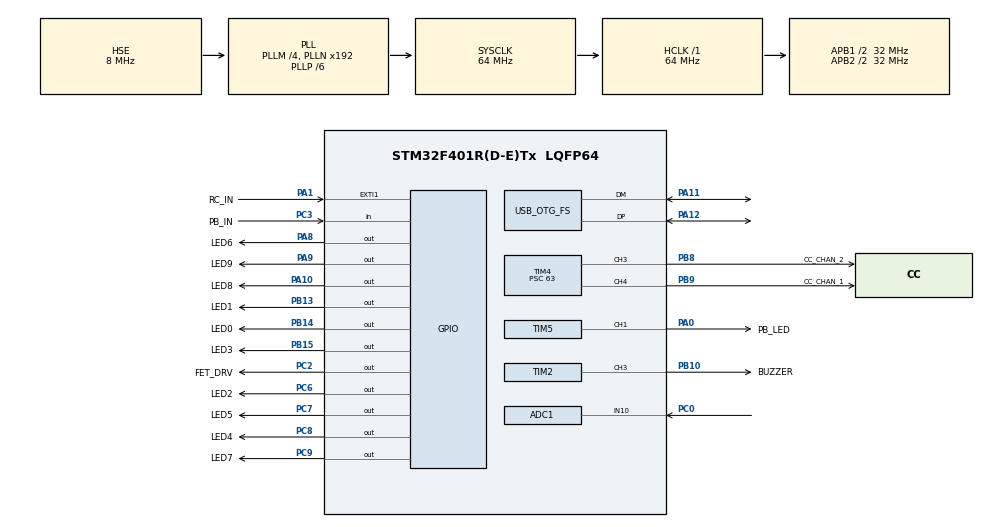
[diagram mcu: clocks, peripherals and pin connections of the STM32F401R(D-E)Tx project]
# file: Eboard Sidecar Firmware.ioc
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ADC1.Channel-4\#ChannelRegularConversion=ADC_CHANNEL_10
ADC1.ContinuousConvMode=ENABLE
ADC1.NbrOfConversionFlag=1
ADC1.Rank-4\#ChannelRegularConversion=1
ADC1.SamplingTime-4\#ChannelRegularConversion=ADC_SAMPLETIME_3CYCLES
ADC1.master=1
Dma.ADC1.0.Direction=DMA_PERIPH_TO_MEMORY
Dma.ADC1.0.FIFOMode=DMA_FIFOMODE_DISABLE
Dma.ADC1.0.Instance=DMA2_Stream0
Dma.ADC1.0.MemDataAlignment=DMA_MDATAALIGN_HALFWORD
Dma.ADC1.0.MemInc=DMA_MINC_ENABLE
Dma.ADC1.0.Mode=DMA_NORMAL
Dma.ADC1.0.PeriphDataAlignment=DMA_PDATAALIGN_HALFWORD
Dma.ADC1.0.PeriphInc=DMA_PINC_DISABLE
Dma.ADC1.0.Priority=DMA_PRIORITY_HIGH
Dma.Request0=ADC1
FREERTOS.INCLUDE_xEventGroupSetBitFromISR=1
FREERTOS.Tasks01=state_machine,8,512,doStateMachine,Default,NULL,Dynamic,NULL,NULL
FREERTOS.configCHECK_FOR_STACK_OVERFLOW=2
FREERTOS.configMAX_TASK_NAME_LEN=32
FREERTOS.configRECORD_STACK_HIGH_ADDRESS=1
FREERTOS.configTIMER_TASK_PRIORITY=48
FREERTOS.configTOTAL_HEAP_SIZE=32768
Mcu.Family=STM32F4
Mcu.Name=STM32F401R(D-E)Tx
Mcu.Package=LQFP64
NVIC.DMA2_Stream0_IRQn=true\:9\:0\:true\:false\:true\:true\:false\:true
NVIC.EXTI1_IRQn=true\:7\:0\:true\:false\:true\:false\:true\:true
NVIC.OTG_FS_IRQn=true\:6\:0\:true\:false\:true\:true\:false\:true
NVIC.PriorityGroup=NVIC_PRIORITYGROUP_4
NVIC.TIM1_TRG_COM_TIM11_IRQn=true\:0\:0\:false\:false\:true\:false\:false\:true
NVIC.TIM3_IRQn=true\:8\:0\:true\:false\:true\:true\:true\:true
NVIC.TimeBase=TIM1_TRG_COM_TIM11_IRQn
NVIC.TimeBaseIP=TIM11
PA0-WKUP.GPIO_Label=PB_LED
PA0-WKUP.Signal=S_TIM5_CH1
PA1.GPIO_Label=RC_IN
PA1.GPIO_ModeDefaultEXTI=GPIO_MODE_IT_RISING_FALLING
PA1.GPIO_PuPd=GPIO_PULLDOWN
PA1.Signal=GPXTI1
PA10.GPIO_Label=LED8
PA10.Signal=GPIO_Output
PA11.Mode=Device_Only
PA11.Signal=USB_OTG_FS_DM
PA12.Mode=Device_Only
PA12.Signal=USB_OTG_FS_DP
PA13.Mode=Serial_Wire
PA13.Signal=SYS_JTMS-SWDIO
PA14.Mode=Serial_Wire
PA14.Signal=SYS_JTCK-SWCLK
PA8.GPIO_Label=LED6
PA8.Signal=GPIO_Output
PA9.GPIO_Label=LED9
PA9.Signal=GPIO_Output
PB10.GPIO_Label=BUZZER
PB10.Signal=S_TIM2_CH3
PB13.GPIO_Label=LED1
PB13.Signal=GPIO_Output
PB14.GPIO_Label=LED0
PB14.Signal=GPIO_Output
PB15.GPIO_Label=LED3
PB15.Signal=GPIO_Output
PB8.GPIO_Label=CC_CHAN_2
PB8.Signal=S_TIM4_CH3
PB9.GPIO_Label=CC_CHAN_1
PB9.Signal=S_TIM4_CH4
PC0.Signal=ADCx_IN10
PC2.GPIO_Label=FET_DRV
PC2.Signal=GPIO_Output
PC3.GPIO_Label=PB_IN
PC3.GPIO_PuPd=GPIO_PULLUP
PC3.Signal=GPIO_Input
PC6.GPIO_Label=LED2
PC6.Signal=GPIO_Output
PC7.GPIO_Label=LED5
PC7.Signal=GPIO_Output
PC8.GPIO_Label=LED4
PC8.Signal=GPIO_Output
PC9.GPIO_Label=LED7
PC9.Signal=GPIO_Output
PH0\ -\ OSC_IN.Mode=HSE-External-Clock-Source
PH0\ -\ OSC_IN.Signal=RCC_OSC_IN
PH1\ -\ OSC_OUT.Mode=HSE-External-Clock-Source
PH1\ -\ OSC_OUT.Signal=RCC_OSC_OUT
ProjectManager.HeapSize=0x400
ProjectManager.StackSize=0x800
ProjectManager.TargetToolchain=STM32CubeIDE
RCC.48MHZClocksFreq_Value=48000000
RCC.AHBFreq_Value=64000000
RCC.APB1CLKDivider=RCC_HCLK_DIV2
RCC.APB1Freq_Value=32000000
RCC.APB1TimFreq_Value=64000000
RCC.APB2CLKDivider=RCC_HCLK_DIV2
RCC.APB2Freq_Value=32000000
RCC.APB2TimFreq_Value=64000000
RCC.CortexFreq_Value=64000000
RCC.HCLKFreq_Value=64000000
RCC.HSE_VALUE=8000000
RCC.HSI_VALUE=16000000
RCC.LSE_VALUE=32768
RCC.PLLM=4
RCC.PLLP=RCC_PLLP_DIV6
RCC.PLLQ=8
RCC.SYSCLKFreq_VALUE=64000000
RCC.SYSCLKSource=RCC_SYSCLKSOURCE_PLLCLK
RCC.VCOOutputFreq_Value=384000000
SH.ADCx_IN10.0=ADC1_IN10,IN10
SH.S_TIM2_CH3.0=TIM2_CH3,Output Compare3 CH3
SH.S_TIM4_CH3.0=TIM4_CH3,PWM Generation3 CH3
SH.S_TIM4_CH4.0=TIM4_CH4,PWM Generation4 CH4
SH.S_TIM5_CH1.0=TIM5_CH1,PWM Generation1 CH1
TIM2.Channel-Output\ Compare3\ CH3=TIM_CHANNEL_3
TIM2.OCMode_3=TIM_OCMODE_TOGGLE
TIM2.Period=1000
TIM2.Prescaler=64
TIM3.Channel-Output\ Compare1\ No\ Output=TIM_CHANNEL_1
TIM3.Period=49999
TIM3.Prescaler=63
TIM4.Channel-PWM\ Generation3\ CH3=TIM_CHANNEL_3
TIM4.Channel-PWM\ Generation4\ CH4=TIM_CHANNEL_4
TIM4.Period=1000
TIM4.Prescaler=63
TIM5.Channel-PWM\ Generation1\ CH1=TIM_CHANNEL_1
TIM5.Period=999
TIM5.Prescaler=63
TIM5.Pulse-PWM\ Generation1\ CH1=127
USB_DEVICE.CLASS_NAME_FS=CDC
USB_DEVICE.PRODUCT_STRING_CDC_FS=EBoard Sidecar
USB_DEVICE.VirtualMode-CDC_FS=Cdc
USB_DEVICE.VirtualModeFS=Cdc_FS
USB_OTG_FS.VirtualMode=Device_Only
VP_FREERTOS_VS_CMSIS_V2.Mode=CMSIS_V2
VP_SYS_VS_tim11.Mode=TIM11
VP_TIM2_VS_ClockSourceINT.Mode=Internal
VP_TIM3_VS_no_output1.Mode=Output Compare1 No Output
VP_USB_DEVICE_VS_USB_DEVICE_CDC_FS.Mode=CDC_FS
board=custom

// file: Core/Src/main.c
/* USER CODE BEGIN Header */
/**
  ******************************************************************************
  * @file           : main.c
  * @brief          : Main program body
  ******************************************************************************
  * @attention
  *
  * <h2><center>&copy; Copyright (c) 2020 STMicroelectronics.
  * All rights reserved.</center></h2>
  *
  * This software component is licensed by ST under Ultimate Liberty license
  * SLA0044, the "License"; You may not use this file except in compliance with
  * the License. You may obtain a copy of the License at:
  *                             www.st.com/SLA0044
  *
  ******************************************************************************
  */
/* USER CODE END Header */
#include "main.h"
#include "cmsis_os.h"
#include "usb_device.h"

/* USER CODE BEGIN Includes */
#include "state_machine.h"
#include "usbd_cdc_if.h"
/* USER CODE END Includes */

ADC_HandleTypeDef hadc1;
DMA_HandleTypeDef hdma_adc1;

TIM_HandleTypeDef htim2;
TIM_HandleTypeDef htim3;
TIM_HandleTypeDef htim4;
TIM_HandleTypeDef htim5;

/* Definitions for state_machine */
osThreadId_t state_machineHandle;
const osThreadAttr_t state_machine_attributes = {
  .name = "state_machine",
  .priority = (osPriority_t) osPriorityLow,
  .stack_size = 512 * 4
};
/* USER CODE BEGIN PV */
//starting timer for HAL tick functions
//weird that this doesn't get thrown in by default
extern TIM_HandleTypeDef htim11;

/* USER CODE END PV */

void SystemClock_Config(void);
static void MX_GPIO_Init(void);
static void MX_DMA_Init(void);
static void MX_TIM2_Init(void);
static void MX_TIM5_Init(void);
static void MX_ADC1_Init(void);
static void MX_TIM3_Init(void);
static void MX_TIM4_Init(void);
void doStateMachine(void *argument);

int main(void)
{

  /* MCU Configuration--------------------------------------------------------*/

  /* Reset of all peripherals, Initializes the Flash interface and the Systick. */
  HAL_Init();

  /* Configure the system clock */
  SystemClock_Config();

  /* Initialize all configured peripherals */
  MX_GPIO_Init();
  MX_DMA_Init();
  MX_TIM2_Init();
  MX_TIM5_Init();
  MX_ADC1_Init();
  MX_TIM3_Init();
  MX_TIM4_Init();
  /* USER CODE BEGIN 2 */
  HAL_TIM_Base_Start_IT(&htim11);
  MX_USB_DEVICE_Init();
  /* USER CODE END 2 */

  /* Init scheduler */
  osKernelInitialize();

  /* Create the thread(s) */
  /* creation of state_machine */
  state_machineHandle = osThreadNew(doStateMachine, NULL, &state_machine_attributes);

  /* Start scheduler */
  osKernelStart();

  /* We should never get here as control is now taken by the scheduler */
  /* Infinite loop */
  while (1)
  {

  }
}

void SystemClock_Config(void)
{
  RCC_OscInitTypeDef RCC_OscInitStruct = {0};
  RCC_ClkInitTypeDef RCC_ClkInitStruct = {0};

  /** Configure the main internal regulator output voltage
  */
  __HAL_RCC_PWR_CLK_ENABLE();
  __HAL_PWR_VOLTAGESCALING_CONFIG(PWR_REGULATOR_VOLTAGE_SCALE2);
  /** Initializes the RCC Oscillators according to the specified parameters
  * in the RCC_OscInitTypeDef structure.
  */
  RCC_OscInitStruct.OscillatorType = RCC_OSCILLATORTYPE_HSE;
  RCC_OscInitStruct.HSEState = RCC_HSE_BYPASS;
  RCC_OscInitStruct.PLL.PLLState = RCC_PLL_ON;
  RCC_OscInitStruct.PLL.PLLSource = RCC_PLLSOURCE_HSE;
  RCC_OscInitStruct.PLL.PLLM = 4;
  RCC_OscInitStruct.PLL.PLLN = 192;
  RCC_OscInitStruct.PLL.PLLP = RCC_PLLP_DIV6;
  RCC_OscInitStruct.PLL.PLLQ = 8;
  if (HAL_RCC_OscConfig(&RCC_OscInitStruct) != HAL_OK)
  {
    Error_Handler();
  }
  /** Initializes the CPU, AHB and APB buses clocks
  */
  RCC_ClkInitStruct.ClockType = RCC_CLOCKTYPE_HCLK|RCC_CLOCKTYPE_SYSCLK
                              |RCC_CLOCKTYPE_PCLK1|RCC_CLOCKTYPE_PCLK2;
  RCC_ClkInitStruct.SYSCLKSource = RCC_SYSCLKSOURCE_PLLCLK;
  RCC_ClkInitStruct.AHBCLKDivider = RCC_SYSCLK_DIV1;
  RCC_ClkInitStruct.APB1CLKDivider = RCC_HCLK_DIV2;
  RCC_ClkInitStruct.APB2CLKDivider = RCC_HCLK_DIV2;

  if (HAL_RCC_ClockConfig(&RCC_ClkInitStruct, FLASH_LATENCY_2) != HAL_OK)
  {
    Error_Handler();
  }
}

static void MX_ADC1_Init(void)
{

  ADC_ChannelConfTypeDef sConfig = {0};

  /** Configure the global features of the ADC (Clock, Resolution, Data Alignment and number of conversion)
  */
  hadc1.Instance = ADC1;
  hadc1.Init.ClockPrescaler = ADC_CLOCK_SYNC_PCLK_DIV2;
  hadc1.Init.Resolution = ADC_RESOLUTION_12B;
  hadc1.Init.ScanConvMode = DISABLE;
  hadc1.Init.ContinuousConvMode = ENABLE;
  hadc1.Init.DiscontinuousConvMode = DISABLE;
  hadc1.Init.ExternalTrigConvEdge = ADC_EXTERNALTRIGCONVEDGE_NONE;
  hadc1.Init.ExternalTrigConv = ADC_SOFTWARE_START;
  hadc1.Init.DataAlign = ADC_DATAALIGN_RIGHT;
  hadc1.Init.NbrOfConversion = 1;
  hadc1.Init.DMAContinuousRequests = DISABLE;
  hadc1.Init.EOCSelection = ADC_EOC_SINGLE_CONV;
  if (HAL_ADC_Init(&hadc1) != HAL_OK)
  {
    Error_Handler();
  }
  /** Configure for the selected ADC regular channel its corresponding rank in the sequencer and its sample time.
  */
  sConfig.Channel = ADC_CHANNEL_10;
  sConfig.Rank = 1;
  sConfig.SamplingTime = ADC_SAMPLETIME_3CYCLES;
  if (HAL_ADC_ConfigChannel(&hadc1, &sConfig) != HAL_OK)
  {
    Error_Handler();
  }

}

static void MX_TIM2_Init(void)
{

  TIM_ClockConfigTypeDef sClockSourceConfig = {0};
  TIM_MasterConfigTypeDef sMasterConfig = {0};
  TIM_OC_InitTypeDef sConfigOC = {0};

  htim2.Instance = TIM2;
  htim2.Init.Prescaler = 64;
  htim2.Init.CounterMode = TIM_COUNTERMODE_UP;
  htim2.Init.Period = 1000;
  htim2.Init.ClockDivision = TIM_CLOCKDIVISION_DIV1;
  htim2.Init.AutoReloadPreload = TIM_AUTORELOAD_PRELOAD_DISABLE;
  if (HAL_TIM_Base_Init(&htim2) != HAL_OK)
  {
    Error_Handler();
  }
  sClockSourceConfig.ClockSource = TIM_CLOCKSOURCE_INTERNAL;
  if (HAL_TIM_ConfigClockSource(&htim2, &sClockSourceConfig) != HAL_OK)
  {
    Error_Handler();
  }
  if (HAL_TIM_OC_Init(&htim2) != HAL_OK)
  {
    Error_Handler();
  }
  sMasterConfig.MasterOutputTrigger = TIM_TRGO_RESET;
  sMasterConfig.MasterSlaveMode = TIM_MASTERSLAVEMODE_DISABLE;
  if (HAL_TIMEx_MasterConfigSynchronization(&htim2, &sMasterConfig) != HAL_OK)
  {
    Error_Handler();
  }
  sConfigOC.OCMode = TIM_OCMODE_TOGGLE;
  sConfigOC.Pulse = 0;
  sConfigOC.OCPolarity = TIM_OCPOLARITY_HIGH;
  sConfigOC.OCFastMode = TIM_OCFAST_DISABLE;
  if (HAL_TIM_OC_ConfigChannel(&htim2, &sConfigOC, TIM_CHANNEL_3) != HAL_OK)
  {
    Error_Handler();
  }
  HAL_TIM_MspPostInit(&htim2);

}

static void MX_TIM3_Init(void)
{

  TIM_MasterConfigTypeDef sMasterConfig = {0};
  TIM_OC_InitTypeDef sConfigOC = {0};

  htim3.Instance = TIM3;
  htim3.Init.Prescaler = 63;
  htim3.Init.CounterMode = TIM_COUNTERMODE_UP;
  htim3.Init.Period = 49999;
  htim3.Init.ClockDivision = TIM_CLOCKDIVISION_DIV1;
  htim3.Init.AutoReloadPreload = TIM_AUTORELOAD_PRELOAD_DISABLE;
  if (HAL_TIM_OC_Init(&htim3) != HAL_OK)
  {
    Error_Handler();
  }
  sMasterConfig.MasterOutputTrigger = TIM_TRGO_RESET;
  sMasterConfig.MasterSlaveMode = TIM_MASTERSLAVEMODE_DISABLE;
  if (HAL_TIMEx_MasterConfigSynchronization(&htim3, &sMasterConfig) != HAL_OK)
  {
    Error_Handler();
  }
  sConfigOC.OCMode = TIM_OCMODE_TIMING;
  sConfigOC.Pulse = 0;
  sConfigOC.OCPolarity = TIM_OCPOLARITY_HIGH;
  sConfigOC.OCFastMode = TIM_OCFAST_DISABLE;
  if (HAL_TIM_OC_ConfigChannel(&htim3, &sConfigOC, TIM_CHANNEL_1) != HAL_OK)
  {
    Error_Handler();
  }

}

static void MX_TIM4_Init(void)
{

  TIM_MasterConfigTypeDef sMasterConfig = {0};
  TIM_OC_InitTypeDef sConfigOC = {0};

  htim4.Instance = TIM4;
  htim4.Init.Prescaler = 63;
  htim4.Init.CounterMode = TIM_COUNTERMODE_UP;
  htim4.Init.Period = 1000;
  htim4.Init.ClockDivision = TIM_CLOCKDIVISION_DIV1;
  htim4.Init.AutoReloadPreload = TIM_AUTORELOAD_PRELOAD_DISABLE;
  if (HAL_TIM_PWM_Init(&htim4) != HAL_OK)
  {
    Error_Handler();
  }
  sMasterConfig.MasterOutputTrigger = TIM_TRGO_RESET;
  sMasterConfig.MasterSlaveMode = TIM_MASTERSLAVEMODE_DISABLE;
  if (HAL_TIMEx_MasterConfigSynchronization(&htim4, &sMasterConfig) != HAL_OK)
  {
    Error_Handler();
  }
  sConfigOC.OCMode = TIM_OCMODE_PWM1;
  sConfigOC.Pulse = 0;
  sConfigOC.OCPolarity = TIM_OCPOLARITY_HIGH;
  sConfigOC.OCFastMode = TIM_OCFAST_DISABLE;
  if (HAL_TIM_PWM_ConfigChannel(&htim4, &sConfigOC, TIM_CHANNEL_3) != HAL_OK)
  {
    Error_Handler();
  }
  if (HAL_TIM_PWM_ConfigChannel(&htim4, &sConfigOC, TIM_CHANNEL_4) != HAL_OK)
  {
    Error_Handler();
  }
  HAL_TIM_MspPostInit(&htim4);

}

static void MX_TIM5_Init(void)
{

  TIM_MasterConfigTypeDef sMasterConfig = {0};
  TIM_OC_InitTypeDef sConfigOC = {0};

  htim5.Instance = TIM5;
  htim5.Init.Prescaler = 63;
  htim5.Init.CounterMode = TIM_COUNTERMODE_UP;
  htim5.Init.Period = 999;
  htim5.Init.ClockDivision = TIM_CLOCKDIVISION_DIV1;
  htim5.Init.AutoReloadPreload = TIM_AUTORELOAD_PRELOAD_DISABLE;
  if (HAL_TIM_PWM_Init(&htim5) != HAL_OK)
  {
    Error_Handler();
  }
  sMasterConfig.MasterOutputTrigger = TIM_TRGO_RESET;
  sMasterConfig.MasterSlaveMode = TIM_MASTERSLAVEMODE_DISABLE;
  if (HAL_TIMEx_MasterConfigSynchronization(&htim5, &sMasterConfig) != HAL_OK)
  {
    Error_Handler();
  }
  sConfigOC.OCMode = TIM_OCMODE_PWM1;
  sConfigOC.Pulse = 127;
  sConfigOC.OCPolarity = TIM_OCPOLARITY_HIGH;
  sConfigOC.OCFastMode = TIM_OCFAST_DISABLE;
  if (HAL_TIM_PWM_ConfigChannel(&htim5, &sConfigOC, TIM_CHANNEL_1) != HAL_OK)
  {
    Error_Handler();
  }
  HAL_TIM_MspPostInit(&htim5);

}

static void MX_DMA_Init(void)
{

  /* DMA controller clock enable */
  __HAL_RCC_DMA2_CLK_ENABLE();

  /* DMA interrupt init */
  /* DMA2_Stream0_IRQn interrupt configuration */
  HAL_NVIC_SetPriority(DMA2_Stream0_IRQn, 9, 0);
  HAL_NVIC_EnableIRQ(DMA2_Stream0_IRQn);

}

static void MX_GPIO_Init(void)
{
  GPIO_InitTypeDef GPIO_InitStruct = {0};

  /* GPIO Ports Clock Enable */
  __HAL_RCC_GPIOH_CLK_ENABLE();
  __HAL_RCC_GPIOC_CLK_ENABLE();
  __HAL_RCC_GPIOA_CLK_ENABLE();
  __HAL_RCC_GPIOB_CLK_ENABLE();

  /*Configure GPIO pin Output Level */
  HAL_GPIO_WritePin(GPIOC, FET_DRV_Pin|LED2_Pin|LED5_Pin|LED4_Pin
                          |LED7_Pin, GPIO_PIN_RESET);

  /*Configure GPIO pin Output Level */
  HAL_GPIO_WritePin(GPIOB, LED1_Pin|LED0_Pin|LED3_Pin, GPIO_PIN_RESET);

  /*Configure GPIO pin Output Level */
  HAL_GPIO_WritePin(GPIOA, LED6_Pin|LED9_Pin|LED8_Pin, GPIO_PIN_RESET);

  /*Configure GPIO pins : FET_DRV_Pin LED2_Pin LED5_Pin LED4_Pin
                           LED7_Pin */
  GPIO_InitStruct.Pin = FET_DRV_Pin|LED2_Pin|LED5_Pin|LED4_Pin
                          |LED7_Pin;
  GPIO_InitStruct.Mode = GPIO_MODE_OUTPUT_PP;
  GPIO_InitStruct.Pull = GPIO_NOPULL;
  GPIO_InitStruct.Speed = GPIO_SPEED_FREQ_LOW;
  HAL_GPIO_Init(GPIOC, &GPIO_InitStruct);

  /*Configure GPIO pin : PB_IN_Pin */
  GPIO_InitStruct.Pin = PB_IN_Pin;
  GPIO_InitStruct.Mode = GPIO_MODE_INPUT;
  GPIO_InitStruct.Pull = GPIO_PULLUP;
  HAL_GPIO_Init(PB_IN_GPIO_Port, &GPIO_InitStruct);

  /*Configure GPIO pin : RC_IN_Pin */
  GPIO_InitStruct.Pin = RC_IN_Pin;
  GPIO_InitStruct.Mode = GPIO_MODE_IT_RISING_FALLING;
  GPIO_InitStruct.Pull = GPIO_PULLDOWN;
  HAL_GPIO_Init(RC_IN_GPIO_Port, &GPIO_InitStruct);

  /*Configure GPIO pins : LED1_Pin LED0_Pin LED3_Pin */
  GPIO_InitStruct.Pin = LED1_Pin|LED0_Pin|LED3_Pin;
  GPIO_InitStruct.Mode = GPIO_MODE_OUTPUT_PP;
  GPIO_InitStruct.Pull = GPIO_NOPULL;
  GPIO_InitStruct.Speed = GPIO_SPEED_FREQ_LOW;
  HAL_GPIO_Init(GPIOB, &GPIO_InitStruct);

  /*Configure GPIO pins : LED6_Pin LED9_Pin LED8_Pin */
  GPIO_InitStruct.Pin = LED6_Pin|LED9_Pin|LED8_Pin;
  GPIO_InitStruct.Mode = GPIO_MODE_OUTPUT_PP;
  GPIO_InitStruct.Pull = GPIO_NOPULL;
  GPIO_InitStruct.Speed = GPIO_SPEED_FREQ_LOW;
  HAL_GPIO_Init(GPIOA, &GPIO_InitStruct);

  /* EXTI interrupt init*/
  HAL_NVIC_SetPriority(EXTI1_IRQn, 7, 0);
  //HAL_NVIC_EnableIRQ(EXTI1_IRQn);

}

void HAL_TIM_PeriodElapsedCallback(TIM_HandleTypeDef *htim)
{
  /* USER CODE BEGIN Callback 0 */

	//if it's our pulse timer, call the overflow function
	if(htim->Instance == TIM3) {
		board_lights_tim_overflow();
	}

  /* USER CODE END Callback 0 */
  if (htim->Instance == TIM11) {
    HAL_IncTick();
  }
}

void Error_Handler(void)
{
}

/************************ (C) COPYRIGHT STMicroelectronics *****END OF FILE****/

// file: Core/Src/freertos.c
/* USER CODE BEGIN Header */
/**
  ******************************************************************************
  * File Name          : freertos.c
  * Description        : Code for freertos applications
  ******************************************************************************
  * @attention
  *
  * <h2><center>&copy; Copyright (c) 2020 STMicroelectronics.
  * All rights reserved.</center></h2>
  *
  * This software component is licensed by ST under Ultimate Liberty license
  * SLA0044, the "License"; You may not use this file except in compliance with
  * the License. You may obtain a copy of the License at:
  *                             www.st.com/SLA0044
  *
  ******************************************************************************
  */
/* USER CODE END Header */

#include "FreeRTOS.h"
#include "task.h"
#include "main.h"

/* Hook prototypes */
void vApplicationStackOverflowHook(xTaskHandle xTask, signed char *pcTaskName);

/* USER CODE BEGIN 4 */
__weak void vApplicationStackOverflowHook(xTaskHandle xTask, signed char *pcTaskName)
{
   /* Run time stack overflow checking is performed if
   configCHECK_FOR_STACK_OVERFLOW is defined to 1 or 2. This hook function is
   called if a stack overflow is detected. */
}
/* USER CODE END 4 */

/************************ (C) COPYRIGHT STMicroelectronics *****END OF FILE****/
